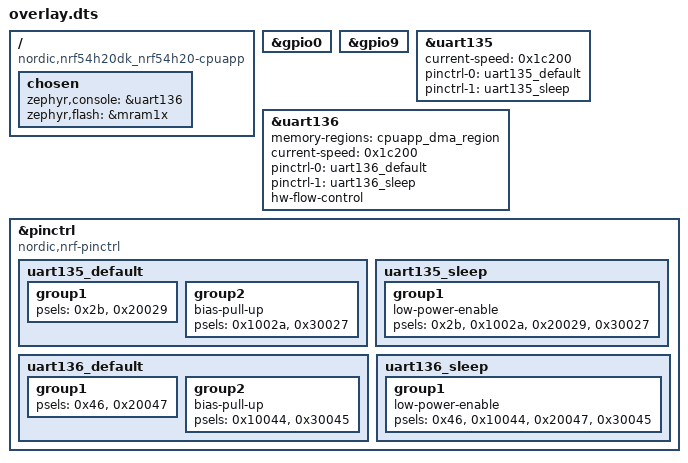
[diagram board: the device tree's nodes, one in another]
/ {
	compatible = "nordic,nrf54h20dk_nrf54h20-cpuapp";
	chosen {
		zephyr,console = &uart136;
		zephyr,flash = &mram1x;
	};
};
&gpio0{
	status = "okay";
};
&gpio9{
	status = "okay";
};
&uart135{
	current-speed = < 0x1c200 >;
	pinctrl-0 = < &uart135_default >;
	pinctrl-1 = < &uart135_sleep >;
	pinctrl-names = "default", "sleep";
};
&uart136{
	status = "okay";
	memory-regions = < &cpuapp_dma_region >;
	current-speed = < 0x1c200 >;
	pinctrl-0 = < &uart136_default >;
	pinctrl-1 = < &uart136_sleep >;
	pinctrl-names = "default", "sleep";
	hw-flow-control;
};
&pinctrl{
	compatible = "nordic,nrf-pinctrl";
	uart135_default: uart135_default {
		group1 {
			psels = < 0x2b >, < 0x20029 >;
		};
		group2 {
			bias-pull-up;
			psels = < 0x1002a >, < 0x30027 >;
		};
	};
	uart135_sleep: uart135_sleep {
		group1 {
			low-power-enable;
			psels = < 0x2b >, < 0x1002a >, < 0x20029 >, < 0x30027 >;
		};
	};
	uart136_default: uart136_default {
		group1 {
			psels = < 0x46 >, < 0x20047 >;
		};
		group2 {
			bias-pull-up;
			psels = < 0x10044 >, < 0x30045 >;
		};
	};
	uart136_sleep: uart136_sleep {
		group1 {
			low-power-enable;
			psels = < 0x46 >, < 0x10044 >, < 0x20047 >, < 0x30045 >;
		};
	};
};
